# Clock_Control_Reg_PRM register map
Vendor: Texas Instruments
Peripheral module from a debugger description file (folder omap36xx).
Registers are 32-bit, access per field, reset 0x4 unless marked. A register's access mark holds for its fields unless they carry their own. Offsets are as the file gives them; lines under a group give offsets from that group; [hi:lo] are bit positions; {n}, {i} and the like mark numbered series; 'fields as' and 'values as' point back to an identical list; <NAME> marks a mode.

## Clock_Control_Reg_PRM
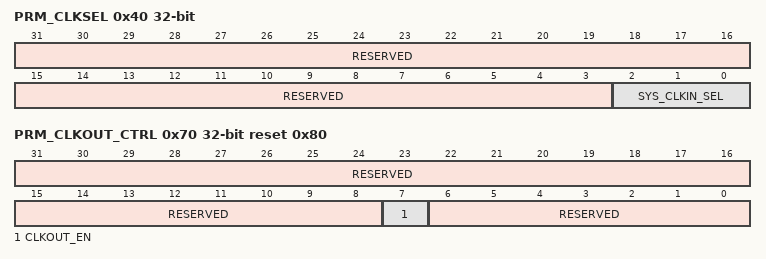
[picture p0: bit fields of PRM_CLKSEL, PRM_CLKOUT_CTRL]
0x40 PRM_CLKSEL — This register controls the selection of the system clock frequency. This register is reset on power-up only.
  [31:3] RESERVED ro — Write 0s for future compatibility. Read returns 0.
  [2:0] SYS_CLKIN_SEL rw — System clock input selection; Other enums: Reserved
    0=OSC_SYS_CLK is 12 MHz; 1=OSC_SYS_CLK is 13 MHz; 2=OSC_SYS_CLK is 19.2 MHz; 3=OSC_SYS_CLK is 26 MHz; 4=OSC_SYS_CLK is 38.4 MHz; 5=OSC_SYS_CLK is 16.8 MHz
0x70 PRM_CLKOUT_CTRL reset 0x80 — This register provides control over the SYS_CLKOUT1 output clock.
  [31:8] RESERVED ro — Write 0s for future compatibility. Read returns 0.
  [7] CLKOUT_EN rw — This bit controls the external output clock (sys_clkout1) activity
    0=sys_clkout1 is disabled; 1=sys_clkout1 is enabled
  [6:0] RESERVED ro — Write 0s for future compatibility. Read returns 0.
